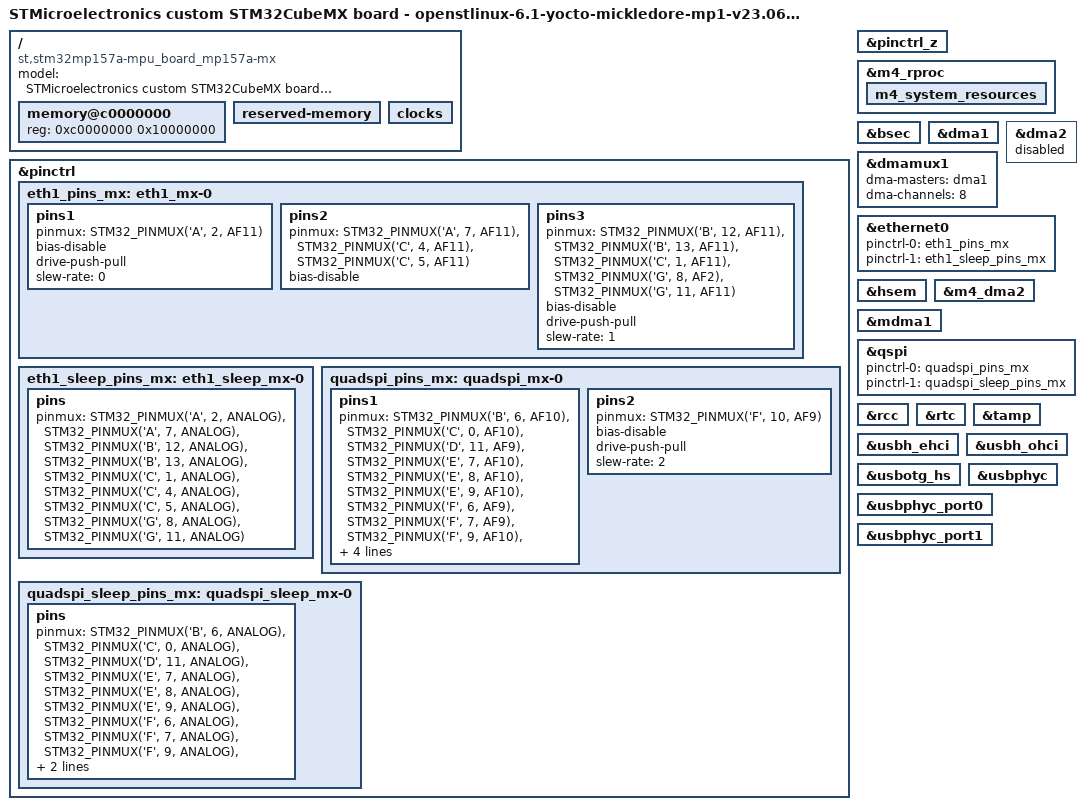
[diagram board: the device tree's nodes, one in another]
// SPDX-License-Identifier: (GPL-2.0-or-later OR BSD-3-Clause)
/*
 * Copyright (C) 2024, STMicroelectronics - All Rights Reserved
 * Author: STM32CubeMX code generation for STMicroelectronics.
 */

/* For more information on Device Tree configuration, please refer to
 * https://wiki.st.com/stm32mpu/wiki/Category:Device_tree_configuration
 */

/dts-v1/;
#include <dt-bindings/pinctrl/stm32-pinfunc.h>

#include "stm32mp157.dtsi"
#include "stm32mp15xa.dtsi"
#include "stm32mp15xxab-pinctrl.dtsi"
#include "stm32mp15-m4-srm.dtsi"

/* USER CODE BEGIN includes */
/* USER CODE END includes */

/ {
	model = "STMicroelectronics custom STM32CubeMX board - openstlinux-6.1-yocto-mickledore-mp1-v23.06.21";
	compatible = "st,stm32mp157a-mpu_board_mp157a-mx", "st,stm32mp157";

	memory@c0000000 {
		device_type = "memory";
		reg = <0xc0000000 0x10000000>;

		/* USER CODE BEGIN memory */
		/* USER CODE END memory */
	};

	reserved-memory {
		#address-cells = <1>;
		#size-cells = <1>;
		ranges;

		/* USER CODE BEGIN reserved-memory */
		/* USER CODE END reserved-memory */
	};

	/* USER CODE BEGIN root */
	/* USER CODE END root */

	clocks{

		/* USER CODE BEGIN clocks */
		/* USER CODE END clocks */
	};

}; /*root*/

&pinctrl {

	eth1_pins_mx: eth1_mx-0 {
		pins1 {
			pinmux = <STM32_PINMUX('A', 2, AF11)>; /* ETH1_MDIO */
			bias-disable;
			drive-push-pull;
			slew-rate = <0>;
		};
		pins2 {
			pinmux = <STM32_PINMUX('A', 7, AF11)>, /* ETH1_CRS_DV */
					 <STM32_PINMUX('C', 4, AF11)>, /* ETH1_RXD0 */
					 <STM32_PINMUX('C', 5, AF11)>; /* ETH1_RXD1 */
			bias-disable;
		};
		pins3 {
			pinmux = <STM32_PINMUX('B', 12, AF11)>, /* ETH1_TXD0 */
					 <STM32_PINMUX('B', 13, AF11)>, /* ETH1_TXD1 */
					 <STM32_PINMUX('C', 1, AF11)>, /* ETH1_MDC */
					 <STM32_PINMUX('G', 8, AF2)>, /* ETH1_CLK */
					 <STM32_PINMUX('G', 11, AF11)>; /* ETH1_TX_EN */
			bias-disable;
			drive-push-pull;
			slew-rate = <1>;
		};
	};

	eth1_sleep_pins_mx: eth1_sleep_mx-0 {
		pins {
			pinmux = <STM32_PINMUX('A', 2, ANALOG)>, /* ETH1_MDIO */
					 <STM32_PINMUX('A', 7, ANALOG)>, /* ETH1_CRS_DV */
					 <STM32_PINMUX('B', 12, ANALOG)>, /* ETH1_TXD0 */
					 <STM32_PINMUX('B', 13, ANALOG)>, /* ETH1_TXD1 */
					 <STM32_PINMUX('C', 1, ANALOG)>, /* ETH1_MDC */
					 <STM32_PINMUX('C', 4, ANALOG)>, /* ETH1_RXD0 */
					 <STM32_PINMUX('C', 5, ANALOG)>, /* ETH1_RXD1 */
					 <STM32_PINMUX('G', 8, ANALOG)>, /* ETH1_CLK */
					 <STM32_PINMUX('G', 11, ANALOG)>; /* ETH1_TX_EN */
		};
	};

	quadspi_pins_mx: quadspi_mx-0 {
		pins1 {
			pinmux = <STM32_PINMUX('B', 6, AF10)>, /* QUADSPI_BK1_NCS */
					 <STM32_PINMUX('C', 0, AF10)>, /* QUADSPI_BK2_NCS */
					 <STM32_PINMUX('D', 11, AF9)>, /* QUADSPI_BK1_IO0 */
					 <STM32_PINMUX('E', 7, AF10)>, /* QUADSPI_BK2_IO0 */
					 <STM32_PINMUX('E', 8, AF10)>, /* QUADSPI_BK2_IO1 */
					 <STM32_PINMUX('E', 9, AF10)>, /* QUADSPI_BK2_IO2 */
					 <STM32_PINMUX('F', 6, AF9)>, /* QUADSPI_BK1_IO3 */
					 <STM32_PINMUX('F', 7, AF9)>, /* QUADSPI_BK1_IO2 */
					 <STM32_PINMUX('F', 9, AF10)>, /* QUADSPI_BK1_IO1 */
					 <STM32_PINMUX('G', 7, AF11)>; /* QUADSPI_BK2_IO3 */
			bias-disable;
			drive-push-pull;
			slew-rate = <1>;
		};
		pins2 {
			pinmux = <STM32_PINMUX('F', 10, AF9)>; /* QUADSPI_CLK */
			bias-disable;
			drive-push-pull;
			slew-rate = <2>;
		};
	};

	quadspi_sleep_pins_mx: quadspi_sleep_mx-0 {
		pins {
			pinmux = <STM32_PINMUX('B', 6, ANALOG)>, /* QUADSPI_BK1_NCS */
					 <STM32_PINMUX('C', 0, ANALOG)>, /* QUADSPI_BK2_NCS */
					 <STM32_PINMUX('D', 11, ANALOG)>, /* QUADSPI_BK1_IO0 */
					 <STM32_PINMUX('E', 7, ANALOG)>, /* QUADSPI_BK2_IO0 */
					 <STM32_PINMUX('E', 8, ANALOG)>, /* QUADSPI_BK2_IO1 */
					 <STM32_PINMUX('E', 9, ANALOG)>, /* QUADSPI_BK2_IO2 */
					 <STM32_PINMUX('F', 6, ANALOG)>, /* QUADSPI_BK1_IO3 */
					 <STM32_PINMUX('F', 7, ANALOG)>, /* QUADSPI_BK1_IO2 */
					 <STM32_PINMUX('F', 9, ANALOG)>, /* QUADSPI_BK1_IO1 */
					 <STM32_PINMUX('F', 10, ANALOG)>, /* QUADSPI_CLK */
					 <STM32_PINMUX('G', 7, ANALOG)>; /* QUADSPI_BK2_IO3 */
		};
	};

	/* USER CODE BEGIN pinctrl */
	/* USER CODE END pinctrl */
};

&pinctrl_z {

	/* USER CODE BEGIN pinctrl_z */
	/* USER CODE END pinctrl_z */
};

&m4_rproc{
	status = "okay";

	/* USER CODE BEGIN m4_rproc */
	/* USER CODE END m4_rproc */

	m4_system_resources{
		status = "okay";

		/* USER CODE BEGIN m4_system_resources */
		/* USER CODE END m4_system_resources */
	};
};

&bsec{
	status = "okay";

	/* USER CODE BEGIN bsec */
	/* USER CODE END bsec */
};

&dma1{
	status = "okay";

	/* USER CODE BEGIN dma1 */
	/* USER CODE END dma1 */
};

&dma2{
	status = "disabled";

	/* USER CODE BEGIN dma2 */
	/* USER CODE END dma2 */
};

&dmamux1{
	status = "okay";

	dma-masters = <&dma1>;
	dma-channels = <8>;

	/* USER CODE BEGIN dmamux1 */
	/* USER CODE END dmamux1 */
};

&ethernet0{
	pinctrl-names = "default", "sleep";
	pinctrl-0 = <&eth1_pins_mx>;
	pinctrl-1 = <&eth1_sleep_pins_mx>;
	status = "okay";

	/* USER CODE BEGIN ethernet0 */
	/* USER CODE END ethernet0 */
};

&hsem{
	status = "okay";

	/* USER CODE BEGIN hsem */
	/* USER CODE END hsem */
};

&m4_dma2{
	status = "okay";

	/* USER CODE BEGIN m4_dma2 */
	/* USER CODE END m4_dma2 */
};

&mdma1{
	status = "okay";

	/* USER CODE BEGIN mdma1 */
	/* USER CODE END mdma1 */
};

&qspi{
	pinctrl-names = "default", "sleep";
	pinctrl-0 = <&quadspi_pins_mx>;
	pinctrl-1 = <&quadspi_sleep_pins_mx>;
	status = "okay";

	/* USER CODE BEGIN qspi */
	/* USER CODE END qspi */
};

&rcc{
	status = "okay";

	/* USER CODE BEGIN rcc */
	/* USER CODE END rcc */
};

&rtc{
	status = "okay";

	/* USER CODE BEGIN rtc */
	/* USER CODE END rtc */
};

&tamp{
	status = "okay";

	/* USER CODE BEGIN tamp */
	/* USER CODE END tamp */
};

&usbh_ehci{
	status = "okay";

	/* USER CODE BEGIN usbh_ehci */
	/* USER CODE END usbh_ehci */
};

&usbh_ohci{
	status = "okay";

	/* USER CODE BEGIN usbh_ohci */
	/* USER CODE END usbh_ohci */
};

&usbotg_hs{
	status = "okay";

	/* USER CODE BEGIN usbotg_hs */
	/* USER CODE END usbotg_hs */
};

&usbphyc{
	status = "okay";

	/* USER CODE BEGIN usbphyc */
	/* USER CODE END usbphyc */
};

&usbphyc_port0{
	status = "okay";

	/* USER CODE BEGIN usbphyc_port0 */
	/* USER CODE END usbphyc_port0 */
};

&usbphyc_port1{
	status = "okay";

	/* USER CODE BEGIN usbphyc_port1 */
	/* USER CODE END usbphyc_port1 */
};

/* USER CODE BEGIN addons */
/* USER CODE END addons */

